# STM32L052 register map
File version: 1.0
CPU: CM0+ r0p0, little endian, MPU, no FPU, 4 interrupt priority bits
Registers are 32-bit, read-write, reset 0x0 unless marked. A register's access mark holds for its fields unless they carry their own. Offsets are from the block's base; [hi:lo] are bit positions; {n}, {i} and the like mark numbered series.

## NVIC — Nested Vectored Interrupt Controller
Base 0xE000E100
0x00 ISER — Interrupt Set Enable Register
  [31:0] SETENA
0x80 ICER — Interrupt Clear Enable Register
  [31:0] CLRENA
0x100 ISPR — Interrupt Set-Pending Register
  [31:0] SETPEND
0x180 ICPR — Interrupt Clear-Pending Register
  [31:0] CLRPEND
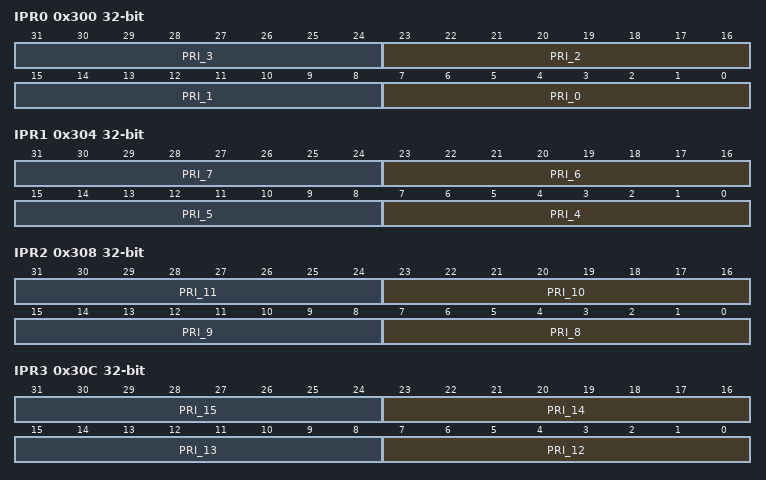
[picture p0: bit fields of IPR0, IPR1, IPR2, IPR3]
0x300 IPR0 — Interrupt Priority Register 0
  [8n+7:8n] PRI_{n} (n=0..3) — priority for interrupt {n}
0x304 IPR1 — Interrupt Priority Register 1
  [8n-25:8n-32] PRI_{n} (n=4..7) — priority for interrupt n
0x308 IPR2 — Interrupt Priority Register 2
  [8n-57:8n-64] PRI_{n} (n=8..11) — priority for interrupt n
0x30C IPR3 — Interrupt Priority Register 3
  [8n-89:8n-96] PRI_{n} (n=12..15) — priority for interrupt n
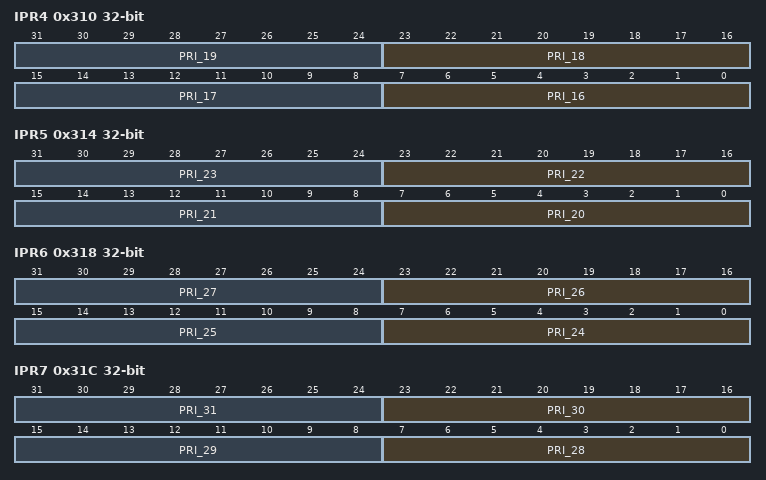
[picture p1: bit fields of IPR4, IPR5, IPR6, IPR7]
0x310 IPR4 — Interrupt Priority Register 4
  [8n-121:8n-128] PRI_{n} (n=16..19) — priority for interrupt n
0x314 IPR5 — Interrupt Priority Register 5
  [8n-153:8n-160] PRI_{n} (n=20..23) — priority for interrupt n
0x318 IPR6 — Interrupt Priority Register 6
  [8n-185:8n-192] PRI_{n} (n=24..27) — priority for interrupt n
0x31C IPR7 — Interrupt Priority Register 7
  [8n-217:8n-224] PRI_{n} (n=28..31) — priority for interrupt n
0x320 IPR8 — Interrupt Priority Register 8

## PWR — Power control
Base 0x40007000
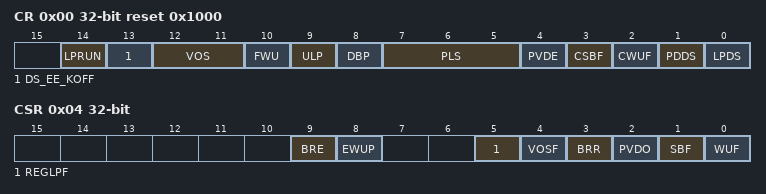
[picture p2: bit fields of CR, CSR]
0x00 CR reset 0x1000 — power control register
  [14] LPRUN — Low power run mode
  [13] DS_EE_KOFF — Deep sleep mode with Flash memory kept off
  [12:11] VOS — Voltage scaling range selection
  [10] FWU — Fast wakeup
  [9] ULP — Ultra-low-power mode
  [8] DBP — Disable backup domain write protection
  [7:5] PLS — PVD level selection
  [4] PVDE — Power voltage detector enable
  [3] CSBF — Clear standby flag
  [2] CWUF — Clear wakeup flag
  [1] PDDS — Power down deepsleep
  [0] LPDS — Low-power deep sleep
0x04 CSR access per field — power control/status register
  [9] BRE rw — Backup regulator enable
  [8] EWUP rw — Enable WKUP pin
  [5] REGLPF ro — Regulator LP flag
  [4] VOSF ro — Voltage Scaling select flag
  [3] BRR ro — Backup regulator ready
  [2] PVDO ro — PVD output
  [1] SBF ro — Standby flag
  [0] WUF ro — Wakeup flag

## Flash
Base 0x40022000
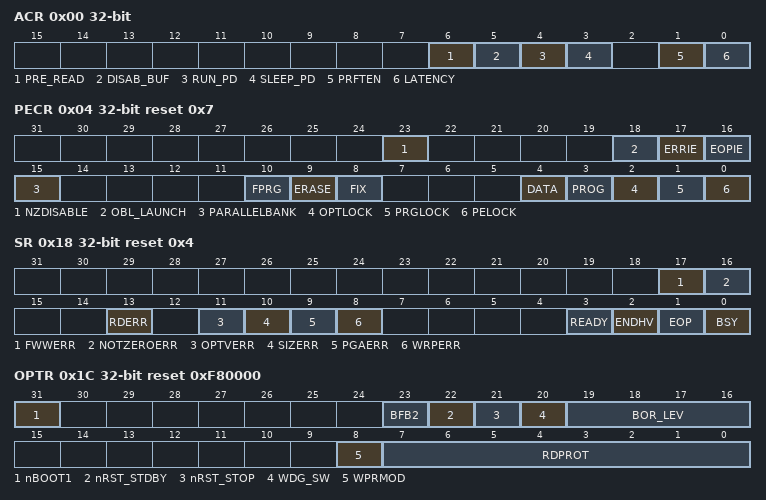
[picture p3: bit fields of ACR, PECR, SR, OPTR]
0x00 ACR — Access control register
  [6] PRE_READ — Pre-read data address
  [5] DISAB_BUF — Disable Buffer
  [4] RUN_PD — Flash mode during Run
  [3] SLEEP_PD — Flash mode during Sleep
  [1] PRFTEN — Prefetch enable
  [0] LATENCY
0x04 PECR reset 0x7 — Program/erase control register
  [23] NZDISABLE — Non-Zero check notification disable
  [18] OBL_LAUNCH — Launch the option byte loading
  [17] ERRIE — Error interrupt enable
  [16] EOPIE — End of programming interrupt enable
  [15] PARALLELBANK — Parallel bank mode
  [10] FPRG — Half Page/Double Word programming mode
  [9] ERASE — Page or Double Word erase mode
  [8] FIX — Fixed time data write for Byte, Half Word and Word programming
  [4] DATA — Data EEPROM selection
  [3] PROG — Program memory selection
  [2] OPTLOCK — Option bytes block lock
  [1] PRGLOCK — Program memory lock
  [0] PELOCK — FLASH_PECR and data EEPROM lock
0x08 PDKEYR wo — Power down key register
  [31:0] PDKEYR — RUN_PD in FLASH_ACR key
0x0C PEKEYR wo — Program/erase key register
  [31:0] PEKEYR — FLASH_PEC and data EEPROM key
0x10 PRGKEYR wo — Program memory key register
  [31:0] PRGKEYR — Program memory key
0x14 OPTKEYR wo — Option byte key register
  [31:0] OPTKEYR — Option byte key
0x18 SR access per field reset 0x4 — Status register
  [17] FWWERR rw
  [16] NOTZEROERR rw
  [13] RDERR rw
  [11] OPTVERR rw — Option validity error
  [10] SIZERR rw — Size error
  [9] PGAERR rw — Programming alignment error
  [8] WRPERR rw — Write protected error
  [3] READY ro — Flash memory module ready after low power mode
  [2] ENDHV ro — End of high voltage
  [1] EOP ro — End of operation
  [0] BSY ro — Write/erase operations in progress
0x1C OPTR ro reset 0xF80000 — Option byte register
  [31] nBOOT1
  [23] BFB2
  [22] nRST_STDBY
  [21] nRST_STOP
  [20] WDG_SW
  [19:16] BOR_LEV
  [8] WPRMOD
  [7:0] RDPROT — Read protection
0x20 WRPROT1 ro — Write protection register
  [31:0] WRPROT1 — Write protection
0x80 WRPROT2 ro — Write protection register
  [15:0] WRPROT2 — Write protection
